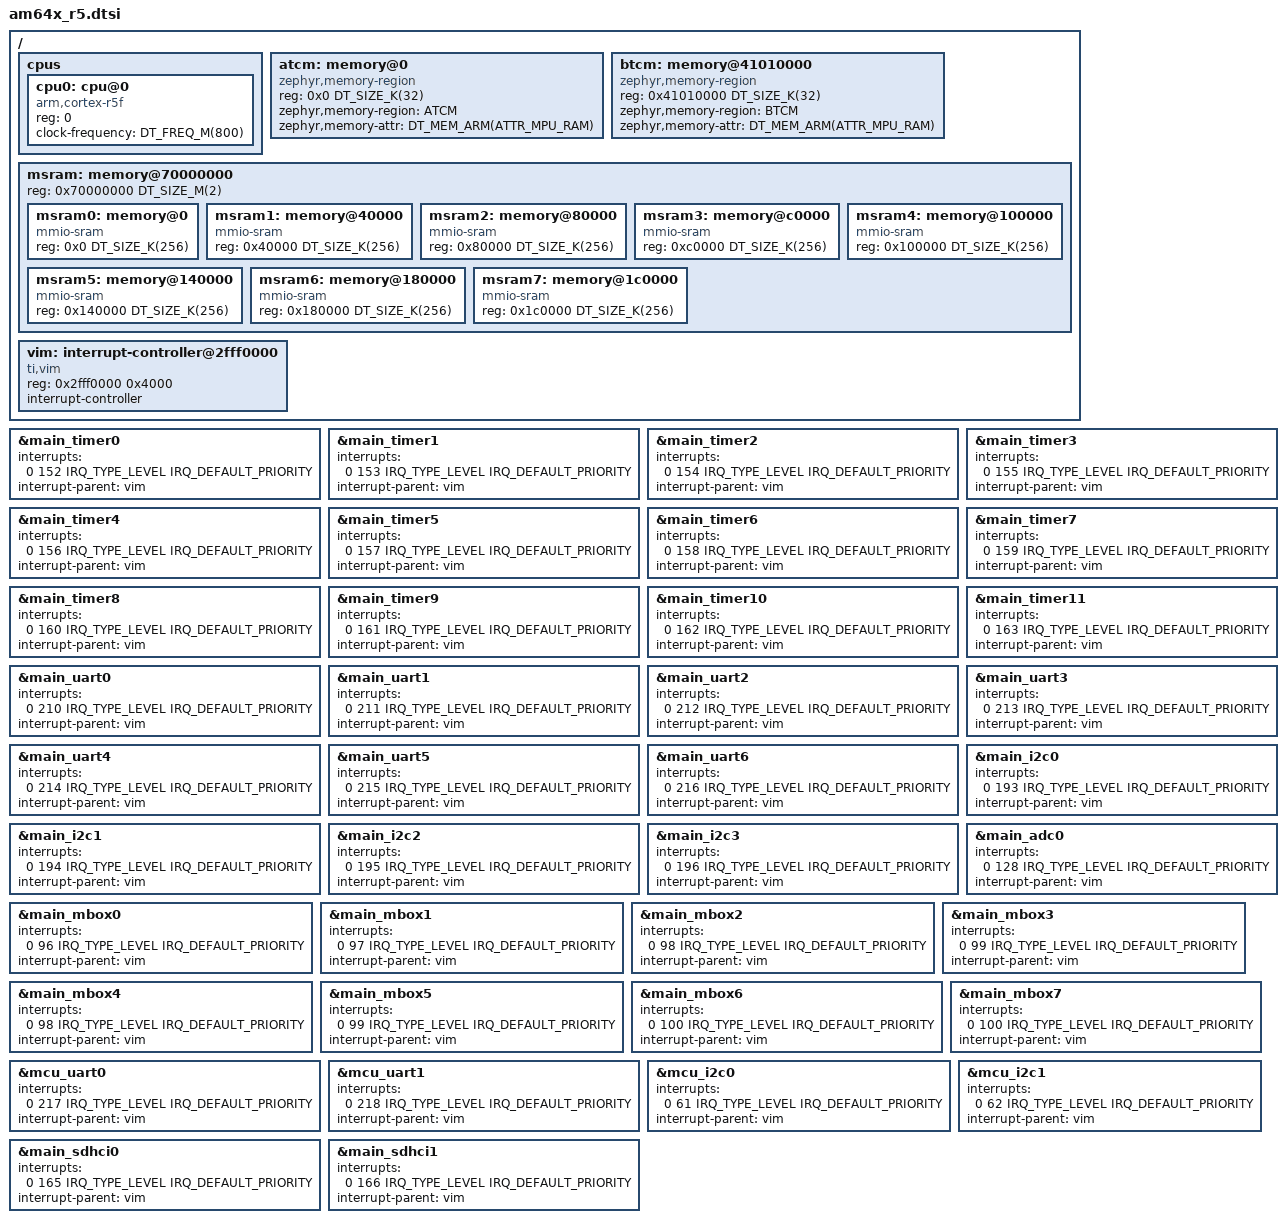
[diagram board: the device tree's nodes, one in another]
/*
 * Copyright (c) 2025 Texas Instruments Incorporated
 *
 * SPDX-License-Identifier: Apache-2.0
 */

#include <mem.h>
#include <arm/armv7-r.dtsi>
#include <zephyr/dt-bindings/memory-attr/memory-attr-arm.h>
#include <zephyr/dt-bindings/interrupt-controller/ti-vim.h>
#include <ti/am64x_main.dtsi>
#include <ti/am64x_mcu.dtsi>

/ {
	#address-cells = <1>;
	#size-cells = <1>;

	cpus {
		#address-cells = <1>;
		#size-cells = <0>;

		cpu0: cpu@0 {
			device_type = "cpu";
			compatible = "arm,cortex-r5f";
			reg = <0>;
			clock-frequency = <DT_FREQ_M(800)>;
		};
	};

	atcm: memory@0 {
		device_type = "memory";
		compatible = "zephyr,memory-region", "mmio-sram";
		reg = <0x0 DT_SIZE_K(32)>;
		zephyr,memory-region = "ATCM";
		zephyr,memory-attr = <DT_MEM_ARM(ATTR_MPU_RAM)>;
	};

	btcm: memory@41010000 {
		device_type = "memory";
		compatible = "zephyr,memory-region", "mmio-sram";
		reg = <0x41010000 DT_SIZE_K(32)>;
		zephyr,memory-region = "BTCM";
		zephyr,memory-attr = <DT_MEM_ARM(ATTR_MPU_RAM)>;
	};

	msram: memory@70000000 {
		reg = <0x70000000 DT_SIZE_M(2)>;
		#address-cells = <1>;
		#size-cells = <1>;
		ranges = <0x0 0x70000000 DT_SIZE_M(2)>;

		msram0: memory@0 {
			compatible = "mmio-sram";
			reg = <0x0 DT_SIZE_K(256)>;
		};

		msram1: memory@40000 {
			compatible = "mmio-sram";
			reg = <0x40000 DT_SIZE_K(256)>;
		};

		msram2: memory@80000 {
			compatible = "mmio-sram";
			reg = <0x80000 DT_SIZE_K(256)>;
		};

		msram3: memory@c0000 {
			compatible = "mmio-sram";
			reg = <0xc0000 DT_SIZE_K(256)>;
		};

		msram4: memory@100000 {
			compatible = "mmio-sram";
			reg = <0x100000 DT_SIZE_K(256)>;
		};

		msram5: memory@140000 {
			compatible = "mmio-sram";
			reg = <0x140000 DT_SIZE_K(256)>;
		};

		msram6: memory@180000 {
			compatible = "mmio-sram";
			reg = <0x180000 DT_SIZE_K(256)>;
		};

		msram7: memory@1c0000 {
			compatible = "mmio-sram";
			reg = <0x1c0000 DT_SIZE_K(256)>;
		};
	};

	vim: interrupt-controller@2fff0000 {
		#address-cells = <1>;
		compatible = "ti,vim";
		reg = <0x2fff0000 0x4000>;
		interrupt-controller;
		#interrupt-cells = <4>; /* {IRQ/FIQ, IRQ_NUM, IRQ_TYPE, IRQ_PRIO} */
	};
};

&main_timer0 {
	interrupts = <0 152 IRQ_TYPE_LEVEL IRQ_DEFAULT_PRIORITY>;
	interrupt-parent = <&vim>;
};

&main_timer1 {
	interrupts = <0 153 IRQ_TYPE_LEVEL IRQ_DEFAULT_PRIORITY>;
	interrupt-parent = <&vim>;
};

&main_timer2 {
	interrupts = <0 154 IRQ_TYPE_LEVEL IRQ_DEFAULT_PRIORITY>;
	interrupt-parent = <&vim>;
};

&main_timer3 {
	interrupts = <0 155 IRQ_TYPE_LEVEL IRQ_DEFAULT_PRIORITY>;
	interrupt-parent = <&vim>;
};

&main_timer4 {
	interrupts = <0 156 IRQ_TYPE_LEVEL IRQ_DEFAULT_PRIORITY>;
	interrupt-parent = <&vim>;
};

&main_timer5 {
	interrupts = <0 157 IRQ_TYPE_LEVEL IRQ_DEFAULT_PRIORITY>;
	interrupt-parent = <&vim>;
};

&main_timer6 {
	interrupts = <0 158 IRQ_TYPE_LEVEL IRQ_DEFAULT_PRIORITY>;
	interrupt-parent = <&vim>;
};

&main_timer7 {
	interrupts = <0 159 IRQ_TYPE_LEVEL IRQ_DEFAULT_PRIORITY>;
	interrupt-parent = <&vim>;
};

&main_timer8 {
	interrupts = <0 160 IRQ_TYPE_LEVEL IRQ_DEFAULT_PRIORITY>;
	interrupt-parent = <&vim>;
};

&main_timer9 {
	interrupts = <0 161 IRQ_TYPE_LEVEL IRQ_DEFAULT_PRIORITY>;
	interrupt-parent = <&vim>;
};

&main_timer10 {
	interrupts = <0 162 IRQ_TYPE_LEVEL IRQ_DEFAULT_PRIORITY>;
	interrupt-parent = <&vim>;
};

&main_timer11 {
	interrupts = <0 163 IRQ_TYPE_LEVEL IRQ_DEFAULT_PRIORITY>;
	interrupt-parent = <&vim>;
};

&main_uart0 {
	interrupts = <0 210 IRQ_TYPE_LEVEL IRQ_DEFAULT_PRIORITY>;
	interrupt-parent = <&vim>;
};

&main_uart1 {
	interrupts = <0 211 IRQ_TYPE_LEVEL IRQ_DEFAULT_PRIORITY>;
	interrupt-parent = <&vim>;
};

&main_uart2 {
	interrupts = <0 212 IRQ_TYPE_LEVEL IRQ_DEFAULT_PRIORITY>;
	interrupt-parent = <&vim>;
};

&main_uart3 {
	interrupts = <0 213 IRQ_TYPE_LEVEL IRQ_DEFAULT_PRIORITY>;
	interrupt-parent = <&vim>;
};

&main_uart4 {
	interrupts = <0 214 IRQ_TYPE_LEVEL IRQ_DEFAULT_PRIORITY>;
	interrupt-parent = <&vim>;
};

&main_uart5 {
	interrupts = <0 215 IRQ_TYPE_LEVEL IRQ_DEFAULT_PRIORITY>;
	interrupt-parent = <&vim>;
};

&main_uart6 {
	interrupts = <0 216 IRQ_TYPE_LEVEL IRQ_DEFAULT_PRIORITY>;
	interrupt-parent = <&vim>;
};

&main_i2c0 {
	interrupts = <0 193 IRQ_TYPE_LEVEL IRQ_DEFAULT_PRIORITY>;
	interrupt-parent = <&vim>;
};

&main_i2c1 {
	interrupts = <0 194 IRQ_TYPE_LEVEL IRQ_DEFAULT_PRIORITY>;
	interrupt-parent = <&vim>;
};

&main_i2c2 {
	interrupts = <0 195 IRQ_TYPE_LEVEL IRQ_DEFAULT_PRIORITY>;
	interrupt-parent = <&vim>;
};

&main_i2c3 {
	interrupts = <0 196 IRQ_TYPE_LEVEL IRQ_DEFAULT_PRIORITY>;
	interrupt-parent = <&vim>;
};

&main_adc0 {
	interrupts = <0 128 IRQ_TYPE_LEVEL IRQ_DEFAULT_PRIORITY>;
	interrupt-parent = <&vim>;
};

&main_mbox0 {
	interrupts = <0 96 IRQ_TYPE_LEVEL IRQ_DEFAULT_PRIORITY>;
	interrupt-parent = <&vim>;
};

&main_mbox1 {
	interrupts = <0 97 IRQ_TYPE_LEVEL IRQ_DEFAULT_PRIORITY>;
	interrupt-parent = <&vim>;
};

&main_mbox2 {
	interrupts = <0 98 IRQ_TYPE_LEVEL IRQ_DEFAULT_PRIORITY>;
	interrupt-parent = <&vim>;
};

&main_mbox3 {
	interrupts = <0 99 IRQ_TYPE_LEVEL IRQ_DEFAULT_PRIORITY>;
	interrupt-parent = <&vim>;
};

&main_mbox4 {
	interrupts = <0 98 IRQ_TYPE_LEVEL IRQ_DEFAULT_PRIORITY>;
	interrupt-parent = <&vim>;
};

&main_mbox5 {
	interrupts = <0 99 IRQ_TYPE_LEVEL IRQ_DEFAULT_PRIORITY>;
	interrupt-parent = <&vim>;
};

&main_mbox6 {
	interrupts = <0 100 IRQ_TYPE_LEVEL IRQ_DEFAULT_PRIORITY>;
	interrupt-parent = <&vim>;
};

&main_mbox7 {
	interrupts = <0 100 IRQ_TYPE_LEVEL IRQ_DEFAULT_PRIORITY>;
	interrupt-parent = <&vim>;
};

&mcu_uart0 {
	interrupts = <0 217 IRQ_TYPE_LEVEL IRQ_DEFAULT_PRIORITY>;
	interrupt-parent = <&vim>;
};

&mcu_uart1 {
	interrupts = <0 218 IRQ_TYPE_LEVEL IRQ_DEFAULT_PRIORITY>;
	interrupt-parent = <&vim>;
};

&mcu_i2c0 {
	interrupts = <0 61 IRQ_TYPE_LEVEL IRQ_DEFAULT_PRIORITY>;
	interrupt-parent = <&vim>;
};

&mcu_i2c1 {
	interrupts = <0 62 IRQ_TYPE_LEVEL IRQ_DEFAULT_PRIORITY>;
	interrupt-parent = <&vim>;
};

&main_sdhci0 {
	interrupts = <0 165 IRQ_TYPE_LEVEL IRQ_DEFAULT_PRIORITY>;
	interrupt-parent = <&vim>;
};

&main_sdhci1 {
	interrupts = <0 166 IRQ_TYPE_LEVEL IRQ_DEFAULT_PRIORITY>;
	interrupt-parent = <&vim>;
};
